# MSP430FR2433 register map
Vendor: msp430gen; File version: v0.4.0-29-g702f6f3-dirty
Registers are 16-bit, read-write, reset 0x0 unless marked. A register's access mark holds for its fields unless they carry their own. Offsets are from the block's base; [hi:lo] are bit positions; {n}, {i} and the like mark numbered series.

## CS — CS Clock System
Base 0x00000180
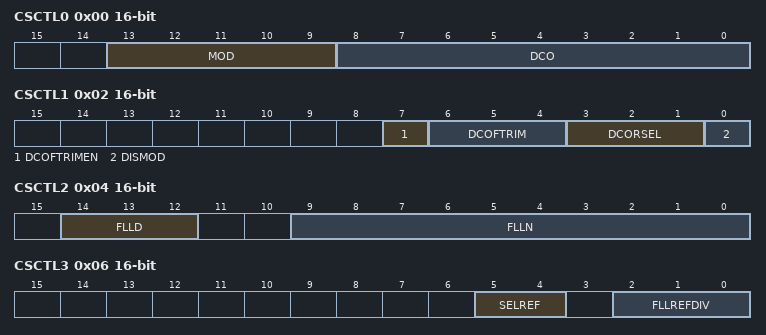
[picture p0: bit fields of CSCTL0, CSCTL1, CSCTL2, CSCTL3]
0x00 CSCTL0 — CS Control Register 0
  [13:9] MOD — Modulation Bit Counter Bit : 0
  [8:0] DCO — DCO TAP Bit : 0
0x02 CSCTL1 — CS Control Register 1
  [7] DCOFTRIMEN — DCO frequency trim enable
  [6:4] DCOFTRIM — DCO frequency trim. Bit: 0
  [3:1] DCORSEL — DCO frequency range select Bit: 0
    0=RANGE_1MHZ (1 MHz); 1=RANGE_2MHZ (2 MHz); 2=RANGE_4MHZ (4 MHz); 3=RANGE_8MHZ (8 MHz); 4=RANGE_12MHZ (12 MHz); 5=RANGE_16MHZ (16 MHz)
  [0] DISMOD — Disable Modulation
0x04 CSCTL2 — CS Control Register 2
  [14:12] FLLD — Loop Divider Bit : 0
    0=/1 (fDCOCLK / 1); 1=/2 (fDCOCLK / 2); 2=/4 (fDCOCLK / 4); 3=/8 (fDCOCLK / 8); 4=/16 (fDCOCLK / 16); 5=/32 (fDCOCLK / 32); 6=fDCOCLK / 40(Only available in 24MHz clock system); 7=fDCOCLK / 48(Only available in 24MHz clock system)
  [9:0] FLLN — FLL Multipier Bit : 0
0x06 CSCTL3 — CS Control Register 3
  [5:4] SELREF — FLL Reference Clock Select Bit : 0
    0=XT1CLK; 1=REFOCLK
  [2:0] FLLREFDIV — Reference Divider Bit : 0
    0=/1 (fFLLREFCLK / 1); 1=/32 (fFLLREFCLK / 32); 2=/64 (fFLLREFCLK / 64); 3=/128 (fFLLREFCLK / 128); 4=/256 (fFLLREFCLK / 256); 5=/512 (fFLLREFCLK / 512); 6=fFLLREFCLK / 640 (only available in 24MHz clock system); 7=fFLLREFCLK / 768(only available in 24MHz clock system)
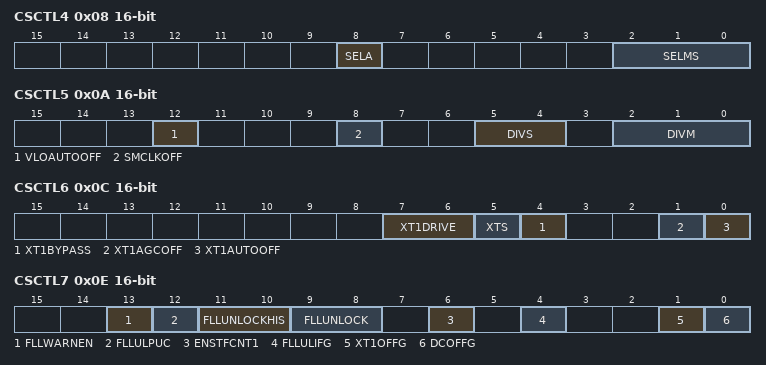
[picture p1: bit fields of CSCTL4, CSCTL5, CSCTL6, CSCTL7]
0x08 CSCTL4 — CS Control Register 4
  [8] SELA — ACLK Source Select Bit: 0
    0=XT1CLK (Source ACLK from XT1CLK with divider (no more than 40kHz)); 1=REFOCLK (Source ACLK from the internal 32kHz clock source)
  [2:0] SELMS — MCLK and SMCLK Source Select Bit: 0
    0=DCOCLKDIV; 1=REFOCLK; 2=XT1CLK; 3=VLOCLK
0x0A CSCTL5 — CS Control Register 5
  [12] VLOAUTOOFF — VLO automatic off enable
  [8] SMCLKOFF
  [5:4] DIVS — SMCLK Divider Bit: 0
    0=/1 (SMCLK = MCLK /1); 1=/2 (SMCLK = MCLK /2); 2=/4 (SMCLK = MCLK /4); 3=/8 (SMCLK = MCLK /8)
  [2:0] DIVM — MCLK Divider Bit: 0
    0=/1 (MCLK = Clock source /1); 1=/2 (MCLK = Clock source /2); 2=/4 (MCLK = Clock source /4); 3=/8 (MCLK = Clock source /8); 4=/16 (MCLK = Clock source /16); 5=/32 (MCLK = Clock source /32); 6=/64 (MCLK = Clock source /64); 7=/128 (MCLK = Clock source /128)
0x0C CSCTL6 — CS Control Register 6
  [7:6] XT1DRIVE — XT1 Drive Level mode Bit 0
    {v}=XT1 Drive Level mode: {v} (v=0..3)
  [5] XTS — 1: Selects high-freq. oscillator
  [4] XT1BYPASS — XT1 bypass mode : 0: internal 1:sourced from external pin
  [1] XT1AGCOFF — XT1 Automatic Gain Control (AGC) disable
  [0] XT1AUTOOFF — XT1 automatic off enable
0x0E CSCTL7 — CS Control Register 7
  [13] FLLWARNEN — Warning enable
    0=DISABLED (FLLUNLOCKHIS status cannot set OFIFG.); 1=ENABLED (FLLUNLOCKHIS status can set OFIFG.)
  [12] FLLULPUC — FLL unlock PUC enable
  [11:10] FLLUNLOCKHIS — Unlock history Bit: 0
    0=LOCKED (FLL is locked. No unlock situation has been detected since the last reset of these bits.); 1=TOO_SLOW (DCOCLK has been too slow since the bits were cleared.); 2=TOO_FAST (DCOCLK has been too fast since the bits were cleared.); 3=TOO_SLOW_AND_FAST (DCOCLK has been both too fast and too slow since the bits were cleared.)
  [9:8] FLLUNLOCK — FLL unlock condition Bit: 0
    0=LOCKED (FLL is locked. No unlock condition currently active.); 1=TOO_SLOW (DCOCLK is currently too slow.); 2=TOO_FAST (DCOCLK is currently too fast.); 3=OUT_OF_RANGE (DCOERROR. DCO out of range.)
  [6] ENSTFCNT1 — Enable start counter for XT1
  [4] FLLULIFG — FLL unlock interrupt flag
  [1] XT1OFFG — XT1 Low Frequency Oscillator Fault Flag
  [0] DCOFFG — DCO fault flag
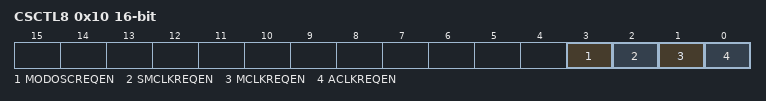
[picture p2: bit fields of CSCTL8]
0x10 CSCTL8 — CS Control Register 8
  [3] MODOSCREQEN — MODOSC Clock Request Enable
  [2] SMCLKREQEN — SMCLK Clock Request Enable
  [1] MCLKREQEN — MCLK Clock Request Enable
  [0] ACLKREQEN — ACLK Clock Request Enable
